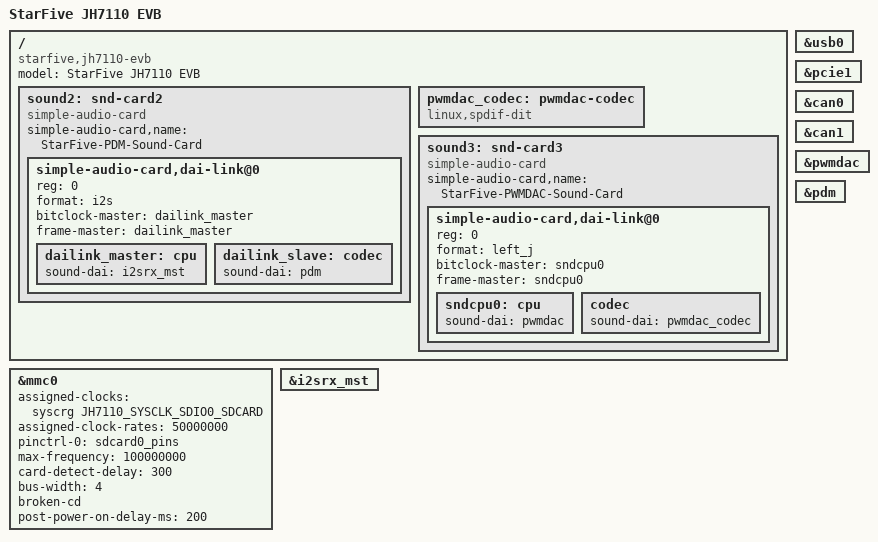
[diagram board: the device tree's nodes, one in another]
// SPDX-License-Identifier: GPL-2.0 OR MIT
/*
 * Copyright (C) 2022 StarFive Technology Co., Ltd.
 */

/dts-v1/;
#include "jh7110-evb.dtsi"

/ {
	model = "StarFive JH7110 EVB";
	compatible = "starfive,jh7110-evb", "starfive,jh7110";

	sound2: snd-card2 {
		compatible = "simple-audio-card";
		#address-cells = <1>;
		#size-cells = <0>;

		simple-audio-card,name = "StarFive-PDM-Sound-Card";
		simple-audio-card,dai-link@0 {
			reg = <0>;
			format = "i2s";
			bitclock-master = <&dailink_master>;
			frame-master = <&dailink_master>;

			dailink_master:cpu {
				sound-dai = <&i2srx_mst>;
			};

			dailink_slave:codec {
				sound-dai = <&pdm>;
			};
		};
	};

	pwmdac_codec: pwmdac-codec {
		compatible = "linux,spdif-dit";
		#sound-dai-cells = <0>;
	};

	sound3: snd-card3 {
		compatible = "simple-audio-card";
		#address-cells = <1>;
		#size-cells = <0>;

		simple-audio-card,name = "StarFive-PWMDAC-Sound-Card";
		simple-audio-card,dai-link@0 {
			reg = <0>;
			format = "left_j";
			bitclock-master = <&sndcpu0>;
			frame-master = <&sndcpu0>;

			sndcpu0: cpu {
				sound-dai = <&pwmdac>;
			};

			codec {
				sound-dai = <&pwmdac_codec>;
			};
		};
	};
};

&mmc0 {
	assigned-clocks = <&syscrg JH7110_SYSCLK_SDIO0_SDCARD>;
	assigned-clock-rates = <50000000>;
	pinctrl-names = "default";
	pinctrl-0 = <&sdcard0_pins>;
	max-frequency = <100000000>;
	card-detect-delay = <300>;
	bus-width = <4>;
	broken-cd;
	post-power-on-delay-ms = <200>;
	status = "okay";
};

&usb0 {
	status = "okay";
};

&pcie1 {
	status = "okay";
};

&can0 {
	status = "okay";
};

&can1 {
	status = "okay";
};

&i2srx_mst {
	status = "okay";
};

&pwmdac {
	status = "okay";
};

&pdm {
	status = "okay";
};
